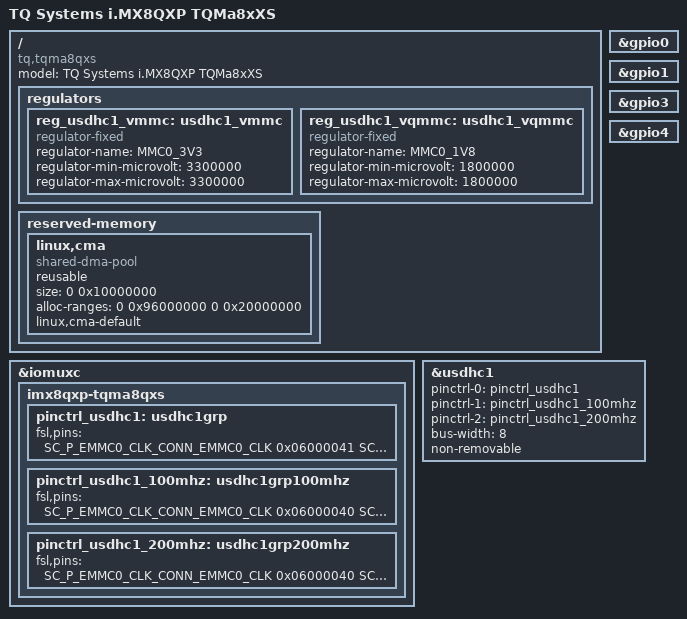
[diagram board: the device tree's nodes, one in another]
/*
 * Copyright 2018 TQ Systems GmbH
 *
 * This program is free software; you can redistribute it and/or
 * modify it under the terms of the GNU General Public License
 * as published by the Free Software Foundation; either version 2
 * of the License, or (at your option) any later version.
 *
 * This program is distributed in the hope that it will be useful,
 * but WITHOUT ANY WARRANTY; without even the implied warranty of
 * MERCHANTABILITY or FITNESS FOR A PARTICULAR PURPOSE.  See the
 * GNU General Public License for more details.
 */

/* First 128KB is for PSCI ATF. */
/* Last 127M is for M4/RPMSG */
/memreserve/ 0x80000000 0x08000000;

#include "fsl-imx8qxp.dtsi"

/ {
	model = "TQ Systems i.MX8QXP TQMa8xXS";
	compatible = "tq,tqma8qxs", "fsl,imx8qxp";

	regulators {
		reg_usdhc1_vmmc: usdhc1_vmmc {
			compatible = "regulator-fixed";
			regulator-name = "MMC0_3V3";
			regulator-min-microvolt = <3300000>;
			regulator-max-microvolt = <3300000>;
		};

		reg_usdhc1_vqmmc: usdhc1_vqmmc {
			compatible = "regulator-fixed";
			regulator-name = "MMC0_1V8";
			regulator-min-microvolt = <1800000>;
			regulator-max-microvolt = <1800000>;
		};
	};

	reserved-memory {
		#address-cells = <2>;
		#size-cells = <2>;
		ranges;

		linux,cma {
			compatible = "shared-dma-pool";
			reusable;
			size = <0 0x10000000>;
			alloc-ranges = <0 0x96000000 0 0x20000000>;
			linux,cma-default;
		};
	};

};

&iomuxc {
	imx8qxp-tqma8qxs {
		pinctrl_usdhc1: usdhc1grp {
			fsl,pins = <
				SC_P_EMMC0_CLK_CONN_EMMC0_CLK		0x06000041
				SC_P_EMMC0_CMD_CONN_EMMC0_CMD		0x00000021
				SC_P_EMMC0_DATA0_CONN_EMMC0_DATA0	0x00000021
				SC_P_EMMC0_DATA1_CONN_EMMC0_DATA1	0x00000021
				SC_P_EMMC0_DATA2_CONN_EMMC0_DATA2	0x00000021
				SC_P_EMMC0_DATA3_CONN_EMMC0_DATA3	0x00000021
				SC_P_EMMC0_DATA4_CONN_EMMC0_DATA4	0x00000021
				SC_P_EMMC0_DATA5_CONN_EMMC0_DATA5	0x00000021
				SC_P_EMMC0_DATA6_CONN_EMMC0_DATA6	0x00000021
				SC_P_EMMC0_DATA7_CONN_EMMC0_DATA7	0x00000021
				SC_P_EMMC0_STROBE_CONN_EMMC0_STROBE	0x06000041
			>;
		};

		pinctrl_usdhc1_100mhz: usdhc1grp100mhz {
			fsl,pins = <
				SC_P_EMMC0_CLK_CONN_EMMC0_CLK		0x06000040
				SC_P_EMMC0_CMD_CONN_EMMC0_CMD		0x00000020
				SC_P_EMMC0_DATA0_CONN_EMMC0_DATA0	0x00000020
				SC_P_EMMC0_DATA1_CONN_EMMC0_DATA1	0x00000020
				SC_P_EMMC0_DATA2_CONN_EMMC0_DATA2	0x00000020
				SC_P_EMMC0_DATA3_CONN_EMMC0_DATA3	0x00000020
				SC_P_EMMC0_DATA4_CONN_EMMC0_DATA4	0x00000020
				SC_P_EMMC0_DATA5_CONN_EMMC0_DATA5	0x00000020
				SC_P_EMMC0_DATA6_CONN_EMMC0_DATA6	0x00000020
				SC_P_EMMC0_DATA7_CONN_EMMC0_DATA7	0x00000020
				SC_P_EMMC0_STROBE_CONN_EMMC0_STROBE	0x06000040
			>;
		};

		pinctrl_usdhc1_200mhz: usdhc1grp200mhz {
			fsl,pins = <
				SC_P_EMMC0_CLK_CONN_EMMC0_CLK		0x06000040
				SC_P_EMMC0_CMD_CONN_EMMC0_CMD		0x00000020
				SC_P_EMMC0_DATA0_CONN_EMMC0_DATA0	0x00000020
				SC_P_EMMC0_DATA1_CONN_EMMC0_DATA1	0x00000020
				SC_P_EMMC0_DATA2_CONN_EMMC0_DATA2	0x00000020
				SC_P_EMMC0_DATA3_CONN_EMMC0_DATA3	0x00000020
				SC_P_EMMC0_DATA4_CONN_EMMC0_DATA4	0x00000020
				SC_P_EMMC0_DATA5_CONN_EMMC0_DATA5	0x00000020
				SC_P_EMMC0_DATA6_CONN_EMMC0_DATA6	0x00000020
				SC_P_EMMC0_DATA7_CONN_EMMC0_DATA7	0x00000020
				SC_P_EMMC0_STROBE_CONN_EMMC0_STROBE	0x06000040
			>;
		};
	};
};

&gpio0 {
	status = "okay";
};

&gpio1 {
	status = "okay";
};

&gpio3 {
	status = "okay";
};

&gpio4 {
	status = "okay";
};

&usdhc1 {
	pinctrl-names = "default", "state_100mhz", "state_200mhz";
	pinctrl-0 = <&pinctrl_usdhc1>;
	pinctrl-1 = <&pinctrl_usdhc1_100mhz>;
	pinctrl-2 = <&pinctrl_usdhc1_200mhz>;
	bus-width = <8>;
	non-removable;
	status = "okay";
};
